# G32F031 register map
File version: 1.0
CPU: CM0PLUS r0p1, little endian, no MPU, no FPU, 2 interrupt priority bits
Registers are 32-bit, read-write, reset 0x0 unless marked. A register's access mark holds for its fields unless they carry their own. Offsets are from the block's base; [hi:lo] are bit positions.

## UART — Universal asynchronous receiver transmitter
Base 0x40003C00
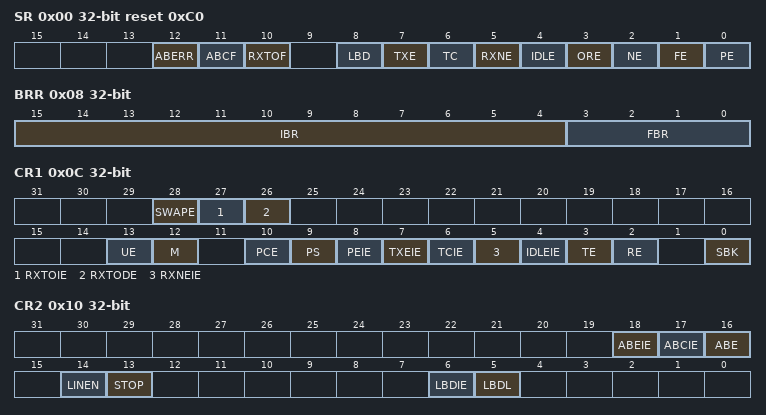
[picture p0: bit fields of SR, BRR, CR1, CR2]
0x00 SR access per field reset 0xC0
  [12] ABERR rw — Auto BR error flag
  [11] ABCF rw — Auto BR complete flag
  [10] RXTOF rw — RX timeout flag
  [8] LBD rw — LIN break detection flag
  [7] TXE ro — Transmit data register empty
  [6] TC ro — Transmission complete
  [5] RXNE ro — Read data register not empty
  [4] IDLE ro — IDLE line detected
  [3] ORE ro — Overrun error
  [2] NE ro — Noise error flag
  [1] FE ro — Framing error
  [0] PE ro — Parity error
0x04 DR
  [8:0] DR — Data value
0x08 BRR
  [15:4] IBR — Integer baud rate
  [3:0] FBR — Fractional baud rate
0x0C CR1
  [28] SWAPE — Swap TX/RX Pins Function Enable
  [27] RXTOIE — Receiver Timeout Interrupt Enable
  [26] RXTODE — Receive Timeout Detection Function Enable
  [13] UE — USART enable
  [12] M — Word length
  [10] PCE — Parity control enable
  [9] PS — Parity selection
  [8] PEIE — PE interrupt enable
  [7] TXEIE — TXE interrupt enable
  [6] TCIE — Transmission complete interrupt enable
  [5] RXNEIE — RXNE interrupt enable
  [4] IDLEIE — IDLE interrupt enable
  [3] TE — Transmitter enable
  [2] RE — Receiver enable
  [0] SBK — Send break
0x10 CR2
  [18] ABEIE — Auto baud error interrupt enable
  [17] ABCIE — Auto baud complete interrupt enable
  [16] ABE — Auto baud enable
  [14] LINEN — LIN mode enable
  [13] STOP — STOP bits
  [6] LBDIE — LIN break detection interrupt enable
  [5] LBDL — LIN break detection length
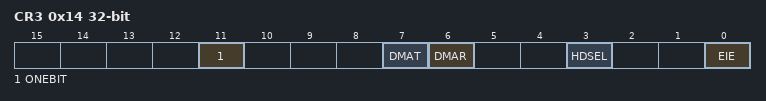
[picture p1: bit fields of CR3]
0x14 CR3
  [11] ONEBIT — Receive data sample mode
  [7] DMAT — DMA enable transmitter
  [6] DMAR — DMA enable receiver
  [3] HDSEL — Half-duplex selection
  [0] EIE — Error interrupt enable
0x1C RXTOR
  [23:0] RXTO — Receiver Timeout Value Setup

## I2C — Inter-Integrated Circuit
Base 0x40004400
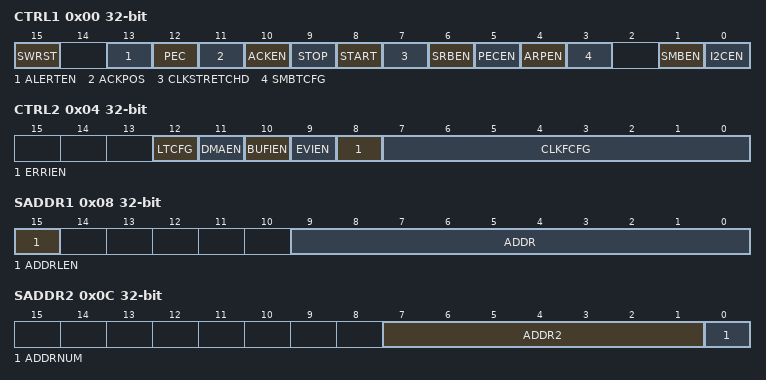
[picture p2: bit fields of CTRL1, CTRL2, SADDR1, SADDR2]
0x00 CTRL1 — control register 1
  [15] SWRST — Software Configure I2C under Reset State
  [13] ALERTEN — SMBus Alert Enable
  [12] PEC — Packet Error Check Transfer Enable
  [11] ACKPOS — Acknowledge /PEC Position Configure
  [10] ACKEN — Acknowledge Transfer Enable
  [9] STOP — Stop Bit Transfer
  [8] START — Start Bit Transfer
  [7] CLKSTRETCHD — Slave Mode Clock Stretching Disable
  [6] SRBEN — Slave Responds Broadcast Enable
  [5] PECEN — PEC Enable
  [4] ARPEN — ARP Enable
  [3] SMBTCFG — SMBus Type Configure
  [1] SMBEN — SMBus Mode Enable
  [0] I2CEN — I2C Enable
0x04 CTRL2 — control register 2
  [12] LTCFG — DMA Last Transfer Configure
  [11] DMAEN — DMA Requests Enable
  [10] BUFIEN — Error interrupt enable
  [9] EVIEN — Event Interrupt Enable
  [8] ERRIEN — Error Interrupt Enable
  [7:0] CLKFCFG — I2C Clock Frequency Configure
0x08 SADDR1 — Slave Mode Address Register 1
  [15] ADDRLEN — Slave Address Length Configure
  [9:0] ADDR — Slave Address Setup
0x0C SADDR2 — Slave Mode Address Register 2
  [7:1] ADDR2 — Slave Dual Address Mode Address Setup
  [0] ADDRNUM — Slave Address Number Configure
0x10 DATA
  [7:0] DATA
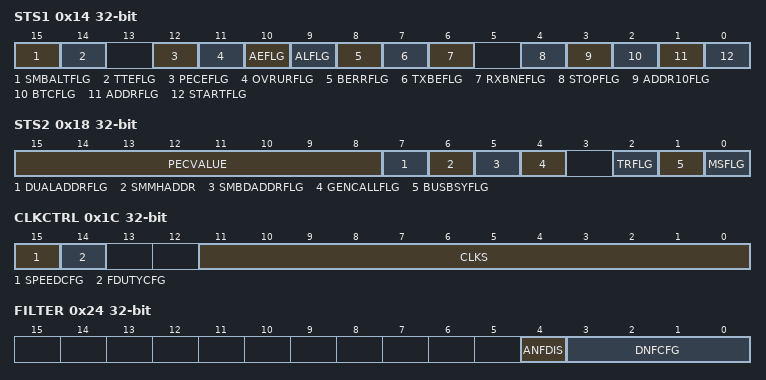
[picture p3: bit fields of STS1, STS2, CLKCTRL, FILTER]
0x14 STS1 access per field — Status register 1
  [15] SMBALTFLG rw — SMBus Alert Occur Flag
  [14] TTEFLG rw — Timeout or Tlow Error Flag
  [12] PECEFLG rw — PEC Error in Reception Flag
  [11] OVRURFLG rw — Overrun/Underrun Flag
  [10] AEFLG rw — Acknowledge Error Flag
  [9] ALFLG rw — Master Mode Arbitration Lost Flag
  [8] BERRFLG rw — Bus Error Flag
  [7] TXBEFLG ro — Transmit Buffer Empty Flag
  [6] RXBNEFLG ro — Receive Buffer Not Empty Flag
  [4] STOPFLG ro — Stop Bit Detection Flag
  [3] ADDR10FLG ro — 10-Bit Address Header Transmit Flag
  [2] BTCFLG ro — Byte Transfer Complete Flag
  [1] ADDRFLG ro — Address Transfer Complete / Receive Match Flag
  [0] STARTFLG ro — Start Bit Sent Finished Flag
0x18 STS2 ro — Status register 2
  [15:8] PECVALUE — Save Packet Error Checking Value
  [7] DUALADDRFLG — Slave Mode Received Dual Address Match Flag
  [6] SMMHADDR — SMBus Device Received Master Header Flag in Slave Mode
  [5] SMBDADDRFLG — SMBus Device Received Default Address Flag in Slave Mode
  [4] GENCALLFLG — Slave Mode Received General Call Address Flag
  [2] TRFLG — Transmitter / Receiver Mode Flag
  [1] BUSBSYFLG — Bus Busy Flag
  [0] MSFLG — Master Slave Mode Flag
0x1C CLKCTRL — Host Clock Control Register
  [15] SPEEDCFG — Master Mode Speed Configure
  [14] FDUTYCFG — Fast Mode Duty Cycle Configure
  [11:0] CLKS — Clock Setup in Fast/Standard Master Mode
0x20 RISETMAX reset 0x2 — Maximum Rise Time Register
  [7:0] RISETMAX — Master Mode Maximum Rise Time in Fast/Standard Mode
0x24 FILTER — Filter Control Register
  [4] ANFDIS — Analog Noise Filter Disable
  [3:0] DNFCFG — Digital Noise Filter Filtering Capability Configure
